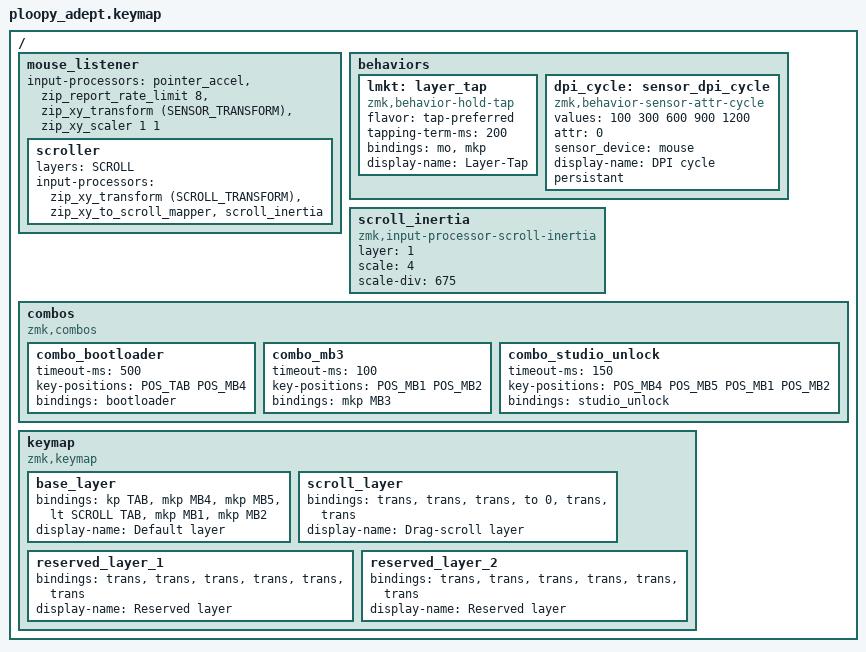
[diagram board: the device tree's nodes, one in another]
// Copyright (c) 2025, George Norton
// SPDX-License-Identifier: MIT

#include <behaviors.dtsi>
#include <behaviors/mouse_keys.dtsi>
#include <behaviors/mouse_move.dtsi>
#include <dt-bindings/zmk/keys.h>
#include <dt-bindings/zmk/mouse.h>
#include <dt-bindings/zmk/input_transform.h>
#include <input/processors.dtsi>
#include <input/processors/report_rate_limit.dtsi>

/* Reserved layer indices — kept so future additions can extend the
 * base/scroll pair without renumbering layer macros or scrambler order.
 */
#define BASE 0
#define SCROLL 1
#define RESERVED1 2
#define RESERVED2 3

/* Position names used by the comments and the combos below. Matches the
 * 6-input matrix declared in ploopy_adept.dts.
 *
 *   ╭──────────┬─────────┬─────────┬──────────────╮
 *   │ Pos 0    │ Pos 1   │ Pos 2   │ Pos 3        │
 *   │ Tab      │ MB4     │ MB5     │ &lt SCROLL   │
 *   │ tall     │ small   │ small   │ tall         │
 *   ├──────────┴─────────┴─────────┴──────────────┤
 *   │ Pos 4                       │ Pos 5       │
 *   │ MB1 (big left)              │ MB2 (big)   │
 *   ╰─────────────────────────────┴─────────────╯
 */
#define POS_TAB 0
#define POS_MB4 1
#define POS_MB5 2
#define POS_SCROLL_KEY 3
#define POS_MB1 4
#define POS_MB2 5

/*
 * Sensor orientation transforms.
 *
 * The PMW3360 in the Ploopy Adept is mounted with its X axis pointing to
 * device-LEFT (instead of device-RIGHT) — i.e. the sensor PCB is flipped
 * along X. Y is already oriented correctly. Therefore only X needs inverting.
 *
 * The same transform is applied inside the SCROLL layer so that drag-scroll
 * keeps the same "spin the ball toward top = page up" direction. If you'd
 * rather have "ball-top = page down" (reverse scroll), OR
 * INPUT_TRANSFORM_Y_INVERT into SCROLL_TRANSFORM only — do not touch
 * SENSOR_TRANSFORM.
 *
 * If you ever flip the sensor PCB or change mounting, tweak SENSOR_TRANSFORM.
 * Available flags (bitwise OR them):
 *   INPUT_TRANSFORM_XY_SWAP  - swap X and Y axes
 *   INPUT_TRANSFORM_X_INVERT - negate X
 *   INPUT_TRANSFORM_Y_INVERT - negate Y
 */
#define SENSOR_TRANSFORM (INPUT_TRANSFORM_X_INVERT)
#define SCROLL_TRANSFORM (INPUT_TRANSFORM_X_INVERT)

/ {
    // Drag-scroll is enabled while the SCROLL layer is held.
    // The base mouse_listener applies the orientation transform so that
    // sensor motion maps onto screen X/Y in the natural direction.
    // Pipeline order (mirrors kaihchang/zmk-simply-adept-dongle-combo):
    //   1. pointer_accel         - velocity-based acceleration, fine control at
    //                                low speeds, flick boost at high speeds
    //   2. zip_report_rate_limit  - cap event rate (limit = 8ms) for stable BT/USB
    //                                reports
    //   3. zip_xy_transform       - sensor orientation fix-up (X_INVERT)
    //   4. zip_xy_scaler          - 3x Y, 2x X amplification to compensate for
    //                                PMW3360 running at 900 CPI vs typical 1200
    mouse_listener {
        // 1:1 (no-op) cursor amplifier. The previous `zip_xy_scaler 3 2`
        // amplified REL_X/REL_Y 2x/1.5x BEFORE the scroll mapper, so a
        // small ball flick produced an oversized WHEEL scroll. Scaling
        // REL_X/REL_Y only scales motion — there's no way to express "fast
        // cursor, slow scroll" without a separate scaler per axis on the
        // scroll side. With this removed, scroll mid-flicks produce 1
        // REL_WHEEL unit per ball count, which is the natural feel.
        input-processors = <&pointer_accel>,
                           <&zip_report_rate_limit 8>,
                           <&zip_xy_transform (SENSOR_TRANSFORM)>,
                           <&zip_xy_scaler 1 1>;

        scroller {
            layers = <SCROLL>;
            // Scroll chain:
            //   zip_xy_to_scroll_mapper  — Y→WHEEL, X→HWHEEL
            //   scroll_inertia            — kinetic coast via mjmjm0101 module
            input-processors = <&zip_xy_transform (SCROLL_TRANSFORM)>,
                               <&zip_xy_to_scroll_mapper>,
                               <&scroll_inertia>;
        };
    };

    behaviors {
        // Modified layer tap that supports mouse keys.
        lmkt: layer_tap {
            compatible = "zmk,behavior-hold-tap";
            #binding-cells = <2>;
            flavor = "tap-preferred";
            tapping-term-ms = <200>;
            bindings = <&mo>, <&mkp>;
            display-name = "Layer-Tap";
        };
        // Behaviour to cycle through DPI values on a keypress
        dpi_cycle: sensor_dpi_cycle {
            compatible = "zmk,behavior-sensor-attr-cycle";
            #binding-cells = <1>;
            values = < 100 300 600 900 1200 >;
            attr = <0>;
            sensor_device = <&mouse>;
            display-name = "DPI cycle";
            persistant;
        };
    };

    // Trackball scroll inertia (mjmjm0101/zmk-input-processor-scroll-inertia).
    // Using README recommended 4:675 scale ratio.
    // layer = <1> so state resets the moment SCROLL toggles off, avoiding
    // the stuck scroll lock on re-entry symptom.
    scroll_inertia: scroll_inertia {
        compatible = "zmk,input-processor-scroll-inertia";
        #input-processor-cells = <0>;
        layer = <1>;
        scale = <4>;
        scale-div = <675>;
    };

    combos {
        compatible = "zmk,combos";
        combo_bootloader {
            // Top-row utility + MB4. Adjacent and easy to hit.
            timeout-ms = <500>;
            key-positions = <POS_TAB POS_MB4>;
            bindings = <&bootloader>;
        };
        combo_mb3 {
            // Pinch-chord the two BIG buttons to send middle click.
            timeout-ms = <100>;
            key-positions = <POS_MB1 POS_MB2>;
            bindings = <&mkp MB3>;
        };
        combo_studio_unlock {
            // 4-key diagonal (MB4 + MB5 + MB1 + MB2) avoids accidental
            // triggers during normal mouse use.
            timeout-ms = <150>;
            key-positions = <POS_MB4 POS_MB5 POS_MB1 POS_MB2>;
            bindings = <&studio_unlock>;
        };
    };

    keymap {
        compatible = "zmk,keymap";

        base_layer {
            // ASCII-art layout (structure matches kaihchang/zmk-simply-adept,
            // tap behavior is plain Tab instead of the kaihchang browser-tab
            // shortcut — see comment block below).
            //
            //   ╭────────────────┬──────────┬─────────┬────────────────────────╮
            //   │  Tab           │ Previous │ Next    │ scroll_layer/Tab       │
            //   │   &kp TAB      │   MB4    │   MB5   │  &lt SCROLL TAB          │
            //   ├────────────────┼──────────┼─────────┼────────────────────────┤
            //   │  Left Click    │          │         │ Right Click            │
            //   │    MB1         │          │         │    MB2                 │
            //   ╰────────────────┴──────────┴─────────┴────────────────────────╯
            //
            // Pos 0 (top-left TALL)  : utility       — tap = plain Tab
            // Pos 1 (top-2nd SMALL)  : mouse back    — MB4
            // Pos 2 (top-3rd SMALL)  : mouse forward — MB5
            // Pos 3 (top-right TALL) : scroll layer  — hold = SCROLL, tap = Tab
            // Pos 4 (bottom-left BIG): primary left  — MB1
            // Pos 5 (bottom-right BIG): primary right — MB2
            // Middle click (MB3) is chorded via combo_mb3 above.
            //
            // Why not kaihchang's `LC(PAGE_UP)` / `LC(PAGE_DOWN)` (the
            // "browser-tab forward/back" shortcuts used by Chrome/Firefox)?
            // Because on the host we tested, LC(PAGE_UP)/DOWN was reported
            // as those exact modifiers+keycode combinations, which some
            // applications don't recognise as "next tab" — they treat it
            // as Ctrl+Page Down (e.g. jumping to a different page in a PDF
            // reader, or scrolling in browsers where Ctrl+Page Down isn't
            // remapped to tab-switch). Sending plain &kp TAB is unambiguous:
            // every host forwards it as the unmodified Tab keycode.
            bindings = <
                &kp TAB                          &mkp MB4   &mkp MB5   &lt SCROLL TAB              &mkp MB1   &mkp MB2
            >;
            display-name = "Default layer";
        };

        scroll_layer {
            // In SCROLL: the same physical pos-3 button (which is &lt SCROLL
            // in BASE) becomes a tap-to-return-to-base so you can exit the
            // SCROLL layer with one tap instead of holding it.
            // All other positions stay transparent so MB4/MB5/MB1/MB2 still
            // work while you're drag-scrolling (e.g. for tap-to-stop-drag).
            bindings = <
                &trans  &trans  &trans  &to 0   &trans  &trans
            >;
            display-name = "Drag-scroll layer";
        };

        reserved_layer_1 {
            bindings = <
                &trans  &trans  &trans  &trans  &trans  &trans
            >;
            display-name = "Reserved layer";
        };

        reserved_layer_2 {
            bindings = <
                &trans  &trans  &trans  &trans  &trans  &trans
            >;
            display-name = "Reserved layer";
        };
    };
};
